# AVR32SD28 register map
Vendor: Atmel; File version: 1.0
CPU: other r0p0, little endian, no MPU, no FPU, 4 interrupt priority bits
Registers are 8-bit, read-write, reset 0x0 unless marked. A register's access mark holds for its fields unless they carry their own. Offsets are from the block's base; [hi:lo] are bit positions; {n}, {i} and the like mark numbered series; 'fields as' and 'values as' point back to an identical list.

## CPU
Base 0x00800030
0x00 SPLIM 16-bit (reset mask 0xFF) — Stack Pointer Limit
0x04 CCP — Configuration Change Protection
  [7:0] CCP — CCP signature
    157=SPM (SPM Instruction Protection); 216=IOREG (IO Register Protection)
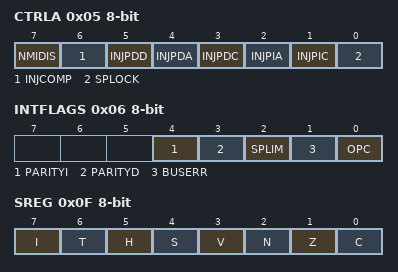
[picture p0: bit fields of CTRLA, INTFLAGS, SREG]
0x05 CTRLA — Control A
  [7] NMIDIS — Disable NMI Request
  [6] INJCOMP — Inject Comparator Error
  [5] INJPDD — Inject Parity Error on Data Bus Data
  [4] INJPDA — Inject Parity Error on Data Bus Address
  [3] INJPDC — Inject Parity Error on Data Bus Control
  [2] INJPIA — Inject Parity Error on Instruction Bus Address
  [1] INJPIC — Inject Parity Error on Instruction Bus Control
  [0] SPLOCK — SPLIM Lock
0x06 INTFLAGS — Interrupt Flags
  [4] PARITYI — Parity Error on Instruction Bus
  [3] PARITYD — Parity Error on Data Bus
  [2] SPLIM — Stack Pointer Limit Error
  [1] BUSERR — Bus Error
  [0] OPC — Illegal Opcode Error
0x0D SP 16-bit (reset mask 0xFF) — Stack Pointer
0x0F SREG — Status Register
  [7] I — Global Interrupt Enable Flag
  [6] T — Transfer Bit
  [5] H — Half Carry Flag
  [4] S — N Exclusive Or V Flag
  [3] V — Two's Complement Overflow Flag
  [2] N — Negative Flag
  [1] Z — Zero Flag
  [0] C — Carry Flag

## CPUINT — Interrupt Controller
Base 0x00800120
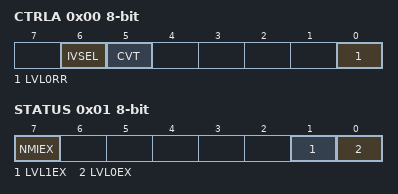
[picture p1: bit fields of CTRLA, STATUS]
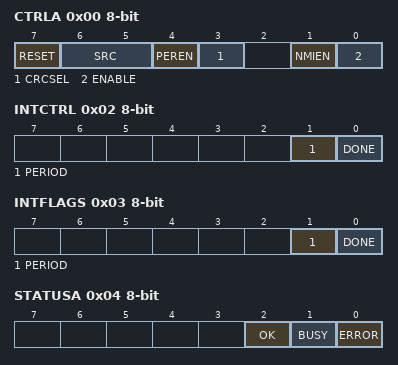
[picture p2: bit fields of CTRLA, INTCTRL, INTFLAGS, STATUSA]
0x00 CTRLA — Control A
  [6] IVSEL — Interrupt Vector Select
  [5] CVT — Compact Vector Table
  [0] LVL0RR — Round-robin Scheduling Enable
0x01 STATUS ro
  [7] NMIEX — Non-maskable Interrupt Executing
  [1] LVL1EX — Level 1 Interrupt Executing
  [0] LVL0EX — Level 0 Interrupt Executing
0x02 LVL0PRI — Interrupt Level 0 Priority
  [7:0] LVL0PRI — Interrupt Level Priority
0x03 LVL1VEC — Interrupt Level 1 Priority Vector
  [7:0] LVL1VEC — Interrupt Vector with High Priority

## CRCSCAN
Base 0x00800130
0x00 CTRLA — Control A
  [7] RESET — Reset CRCSCAN
  [6:5] SRC — CRC Source
    0=BOOT (The CRC is performed on the boot section of Flash); 1=CODE (The CRC is performed on the application code section of Flash); 2=DATA (The CRC is performed on the application data section of Flash); 3=MANUAL (Manual mode, CRC is performed on data written to DATA)
  [4] PEREN — Enable Periodic Timer
    0=DISABLE (The periodic timer is disabled); 1=ENABLE (The periodic timer is enabled)
  [3] CRCSEL — CRC Mode Select
    0=CRC16 (The CRC is performed using CRC16); 1=CRC32 (The CRC is performed using CRC32)
  [1] NMIEN — Enable NMI Trigger
  [0] ENABLE — Enable CRCSCAN
0x01 CTRLB wo — Control B
  [0] EINJ — Inject CRC error
0x02 INTCTRL — Interrupt Control
  [1] PERIOD — Scan Period Done Interrupt Enable
  [0] DONE — Scan Done Interrupt Enable
0x03 INTFLAGS — Interrupt Flags
  [1] PERIOD — Scan Period Done
  [0] DONE — Scan Done
0x04 STATUSA ro
  [2] OK — CRC OK
  [1] BUSY — CRC BUSY
  [0] ERROR — Error Signal driving NMI
0x05 SCANADR ro — Scan Address
  [7:0] SCANADR — Address Being Scanned
0x06 DATA wo — Input Data
0x08 CRC 32-bit ro (reset mask 0xFF) — CRC Result

## DAC0 — Digital to Analog Converter
Base 0x008006A0
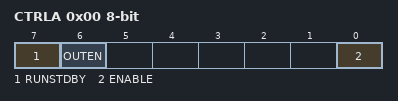
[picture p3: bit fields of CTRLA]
0x00 CTRLA — Control Register A
  [7] RUNSTDBY — Run in Standby Mode
  [6] OUTEN — Output Buffer Enable
  [0] ENABLE — DAC Enable
0x02 DATA 16-bit (reset mask 0xFF)
  [15:6] DATA

## ERRCTRL — Error Controller
Base 0x00800E40
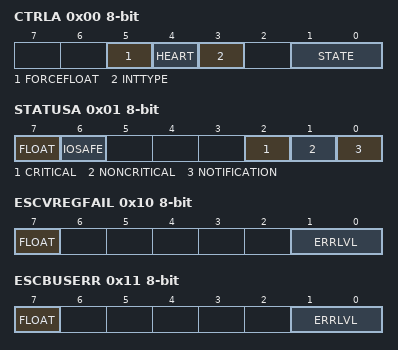
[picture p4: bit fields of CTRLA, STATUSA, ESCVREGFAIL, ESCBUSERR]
0x00 CTRLA — Control A
  [5] FORCEFLOAT — Force I/O Float
  [4] HEART — Heartbeat Enable
  [3] INTTYPE — ALARM State Interrupt Type
    0=INT (Interrupt); 1=NMI (Non-maskable interrupt)
  [1:0] STATE — ERRCTRL State
    0=CONFIG (Configuration state); 1=NORMAL (Normal state); 2=ALARM (Alarm state); 3=FAULT (Fault state)
0x01 STATUSA ro
  [7] FLOAT — Float I/O pins
    0=NORMAL (I/O pins are not forced to floating state); 1=FLOAT (I/O pins are forced to floating state)
  [6] IOSAFE — All I/O pins are in safe state
    0=NOSAFE (One or more I/O pins are not in safe state); 1=SAFE (All I/O pins are in a safe state)
  [2] CRITICAL — Critical Error Detected
    0=NOERROR (There are no Critical errors in the system); 1=ERROR (There are one or more Critical errors in the system)
  [1] NONCRITICAL — Noncritical Error Detected
    0=NOERROR (There are no Noncritical errors in the system); 1=ERROR (There are one or more Noncritical errors in the system)
  [0] NOTIFICATION — Notification Error Detected
    0=NOERROR (There are no Notification errors in the system); 1=ERROR (There are one or more Notification errors in the system)
0x02 TIMEOUT — Timeout Value
0x03 TIMECNT ro — Timeout Counter
  [7:0] TIMECNT — Timeout Counter Value
0x04 CAUSE ro — Reset Cause
  [4:0] CAUSE
    0=VREGFAIL (VREG Low/High voltage detect); 1=BUSERR (Bus Error on data bus or parity error on data); 2=RAM2 (Data (RAM) ECC double bit or comparator error); 3=FLASH2 (Flash ECC double bit or comparator error); 4=OPC (Illegal opcode instruction or parity error on fetched instruction); 5=SPLIM (Stack Pointer Limit); 6=RAM1 (Data (RAM) ECC single bit error); 7=FLASH1 (Flash ECC single bit error); 8=VREGWARN (VREG diagnostic enter/exit or other SLPCTRL error); 9=CFD0; 10=CFD1; 11=CFM0 (CFM Frequency Error 0); 12=CFM1 (CFM Frequency Error 1); 13=SWDT (SWDT Error); 14=EEPROM (EEPROM ECC error); 15=EVSYS0 (Event system input 0); 16=EVSYS1 (Event system input 1)
0x10 ESCVREGFAIL — Error Source Control VREGFAIL
  [7] FLOAT — Float all I/O pins
  [1:0] ERRLVL — Error Severity Level
    0=CRITICAL (Critical error); 2=NONCRITICAL (Noncritical error (reset value)); 3=NOTIFICATION (Notification error)
0x11 ESCBUSERR — Error Source Control BUSERR
  fields as ESCVREGFAIL
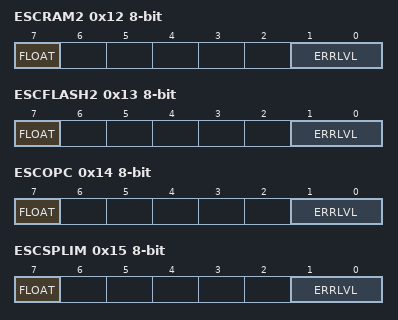
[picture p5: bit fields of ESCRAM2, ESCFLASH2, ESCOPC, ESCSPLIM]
0x12 ESCRAM2 — Error Source Control RAM2
  fields as ESCVREGFAIL
0x13 ESCFLASH2 — Error Source Control FLASH2
  fields as ESCVREGFAIL
0x14 ESCOPC — Error Source Control OPC
  fields as ESCVREGFAIL
0x15 ESCSPLIM — Error Source Control SPLIM
  fields as ESCVREGFAIL
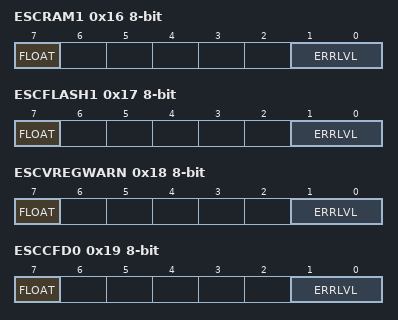
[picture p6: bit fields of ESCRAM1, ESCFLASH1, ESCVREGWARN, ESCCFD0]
0x16 ESCRAM1 — Error Source Control RAM1
  fields as ESCVREGFAIL
0x17 ESCFLASH1 — Error Source Control FLASH1
  fields as ESCVREGFAIL
0x18 ESCVREGWARN — Error Source Control VREGWARN
  fields as ESCVREGFAIL
0x19 ESCCFD0 — Error Source Control CFD0
  fields as ESCVREGFAIL
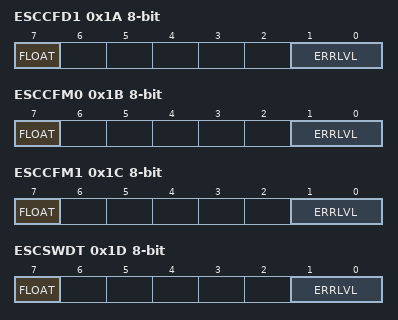
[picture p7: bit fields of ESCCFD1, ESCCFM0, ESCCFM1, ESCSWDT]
0x1A ESCCFD1 — Error Source Control CFD1
  fields as ESCVREGFAIL
0x1B ESCCFM0 — Error Source Control CFM0
  fields as ESCVREGFAIL
0x1C ESCCFM1 — Error Source Control CFM1
  fields as ESCVREGFAIL
0x1D ESCSWDT — Error Source Control SWDT
  fields as ESCVREGFAIL
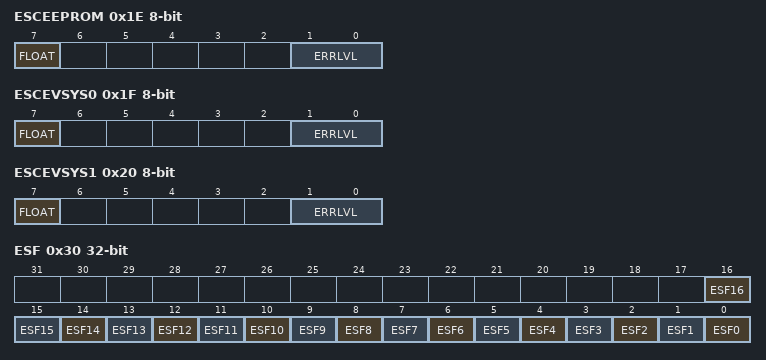
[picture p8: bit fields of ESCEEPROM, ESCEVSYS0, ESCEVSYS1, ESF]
0x1E ESCEEPROM — Error Source Control EEPROM
  fields as ESCVREGFAIL
0x1F ESCEVSYS0 — Error Source Control EVSYS0
  fields as ESCVREGFAIL
0x20 ESCEVSYS1 — Error Source Control EVSYS1
  fields as ESCVREGFAIL
0x30 ESF 32-bit (reset mask 0xFF) — Error Status Flags
  [n] ESF{n} (n=0..16) — Error Status Flag {n}
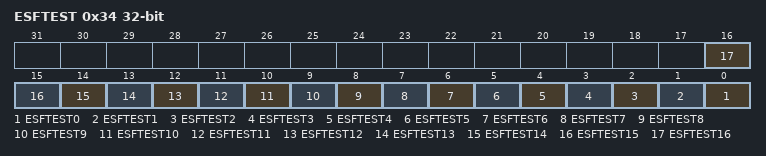
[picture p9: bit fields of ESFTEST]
0x34 ESFTEST 32-bit wo (reset mask 0xFF) — Error Status Flag Test Injection
  [n] ESFTEST{n} (n=0..16) — Error Status Flag Test Injection {n}
